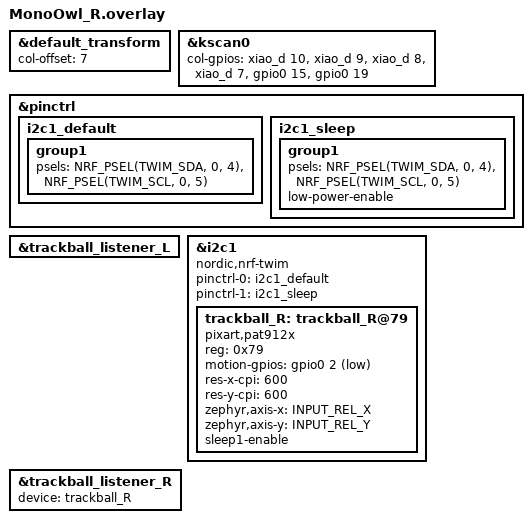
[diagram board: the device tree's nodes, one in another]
#include "MonoOwl.dtsi"
#include <dt-bindings/zmk/input_transform.h>
#include <input/processors.dtsi>

&default_transform {
    col-offset = <7>;
};

&kscan0 {
        col-gpios
            = <&xiao_d 10 (GPIO_ACTIVE_HIGH)>
            , <&xiao_d 9 (GPIO_ACTIVE_HIGH)>
            , <&xiao_d 8 (GPIO_ACTIVE_HIGH)>
            , <&xiao_d 7 (GPIO_ACTIVE_HIGH)>
            , <&gpio0 15 (GPIO_ACTIVE_HIGH)>
            , <&gpio0 19 (GPIO_ACTIVE_HIGH)>
            ;
};

&pinctrl {
    	i2c1_default: i2c1_default {
		group1 {
			psels = <NRF_PSEL(TWIM_SDA, 0, 4)>,
				<NRF_PSEL(TWIM_SCL, 0, 5)>;
		};
	};

	i2c1_sleep: i2c1_sleep {
		group1 {
			psels = <NRF_PSEL(TWIM_SDA, 0, 4)>,
				<NRF_PSEL(TWIM_SCL, 0, 5)>;
			low-power-enable;
		};
	};
};

&trackball_listener_L {
    status = "okay";
};

&i2c1 {
	status = "okay";
	compatible = "nordic,nrf-twim";
	pinctrl-0 = <&i2c1_default>;
	pinctrl-1 = <&i2c1_sleep>;
	pinctrl-names = "default", "sleep";

	trackball_R: trackball_R@79 {
		compatible = "pixart,pat912x";
		reg = <0x79>;
		status = "okay";
		motion-gpios = <&gpio0 2 (GPIO_ACTIVE_LOW | GPIO_PULL_UP)>;
		res-x-cpi = <600>;
		res-y-cpi = <600>;
		zephyr,axis-x = <INPUT_REL_X>;
		zephyr,axis-y = <INPUT_REL_Y>;
		sleep1-enable;
	};
};

&trackball_listener_R {
    status = "okay";
    device = <&trackball_R>;
};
